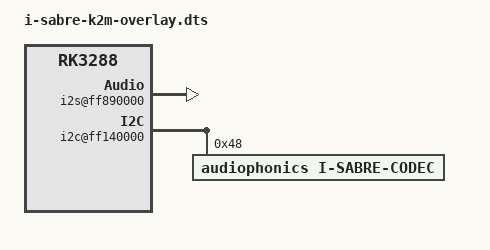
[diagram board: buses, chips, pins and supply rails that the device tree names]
// Definitions for I-Sabre K2M
/dts-v1/;
/plugin/;

/ {
	compatible = "rockchip,rk3288";

	fragment@0 {
		target-path ="/sound-simple-card";
		__overlay__ {
			status = "disabled";
		};
	};

	fragment@1 {
		target-path = "/";
		__overlay__ {
			i-sabre-k2m {
				compatible = "audiophonics,i-sabre-k2m";
				i2s-controller = <&i2s>;
				status = "okay";
			};
		};
	};

	fragment@2 {
		target-path = "/i2s@ff890000";
		__overlay__ {
			rockchip,playback-channels = <2>;
			status = "okay";
		};
	};

	fragment@3 {
		target-path = "/i2c@ff140000";
		__overlay__ {
			#address-cells = <1>;
			#size-cells = <0>;
			status = "okay";

			i-sabre-codec@48 {
				#sound-dai-cells = <0>;
				compatible = "audiophonics,i-sabre-codec";
				reg = <0x48>;
				status = "okay";
			};
		};
	};

};
